# PIC18LF448 register map
Vendor: Microchip
Registers are 8-bit, read-write, no defined reset value unless marked. A register's access mark holds for its fields unless they carry their own. Addresses are absolute, and some are shared; only a register's first bit layout is shown; [hi:lo] are bit positions; {n}, {i} and the like mark numbered series; 'fields as' and 'values as' point back to an identical list.

## SFR
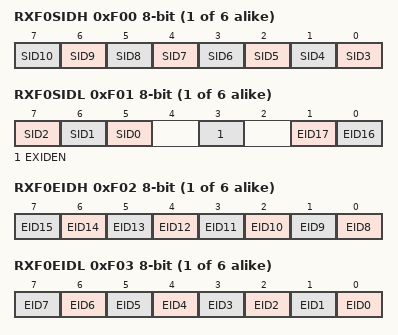
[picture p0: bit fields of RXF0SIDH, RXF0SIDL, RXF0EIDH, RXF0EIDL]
{0xF00+4i} RXF{i}SIDH (i=0..5) — (power-on value xxxxxxxx)
  [n-3] SID{n} (n=3..10)
{0xF01+4i} RXF{i}SIDL (i=0..5) — (power-on value xxx-x-xx)
  [7] SID2, [6] SID1, [5] SID0, [3] EXIDEN, [1] EID17, [0] EID16
{0xF02+4i} RXF{i}EIDH (i=0..5) — (power-on value xxxxxxxx)
  [n-8] EID{n} (n=8..15)
{0xF03+4i} RXF{i}EIDL (i=0..5) — (power-on value xxxxxxxx)
  [n] EID{n} (n=0..7)
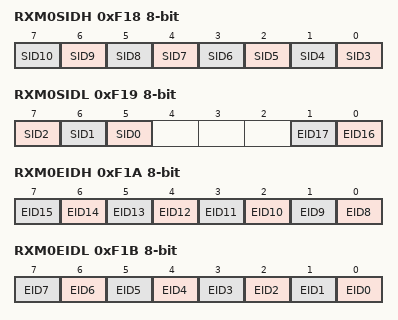
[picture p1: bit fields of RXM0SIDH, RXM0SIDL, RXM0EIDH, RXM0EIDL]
0xF18 RXM0SIDH — (power-on value xxxxxxxx)
  [n-3] SID{n} (n=3..10)
0xF19 RXM0SIDL — (power-on value xxx---xx)
  [7] SID2, [6] SID1, [5] SID0, [1] EID17, [0] EID16
0xF1A RXM0EIDH — (power-on value xxxxxxxx)
  [n-8] EID{n} (n=8..15)
0xF1B RXM0EIDL — (power-on value xxxxxxxx)
  [n] EID{n} (n=0..7)
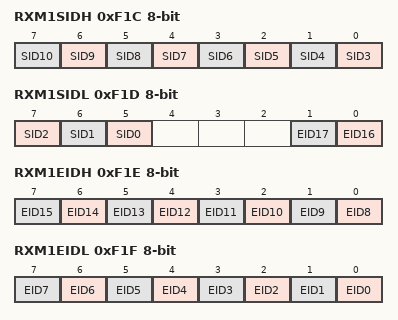
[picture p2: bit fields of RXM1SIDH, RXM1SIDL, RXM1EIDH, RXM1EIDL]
0xF1C RXM1SIDH — (power-on value xxxxxxxx)
  [n-3] SID{n} (n=3..10)
0xF1D RXM1SIDL — (power-on value xxx---xx)
  [7] SID2, [6] SID1, [5] SID0, [1] EID17, [0] EID16
0xF1E RXM1EIDH — (power-on value xxxxxxxx)
  [n-8] EID{n} (n=8..15)
0xF1F RXM1EIDL — (power-on value xxxxxxxx)
  [n] EID{n} (n=0..7)
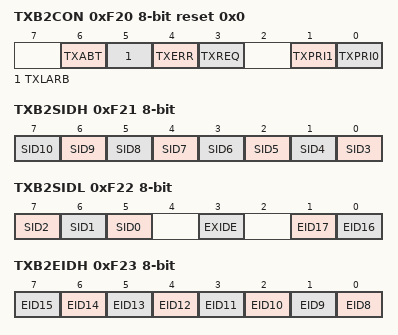
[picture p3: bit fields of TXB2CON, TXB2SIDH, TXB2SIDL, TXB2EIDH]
0xF20 TXB2CON reset 0x0
  [6] TXABT ro, [5] TXLARB ro, [4] TXERR ro, [3] TXREQ, [1] TXPRI1, [0] TXPRI0
0xF21 TXB2SIDH — (power-on value xxxxxxxx)
  [n-3] SID{n} (n=3..10)
0xF22 TXB2SIDL — (power-on value xxxxxxxx)
  [7] SID2, [6] SID1, [5] SID0, [3] EXIDE, [1] EID17, [0] EID16
0xF23 TXB2EIDH — (power-on value xxxxxxxx)
  [n-8] EID{n} (n=8..15)
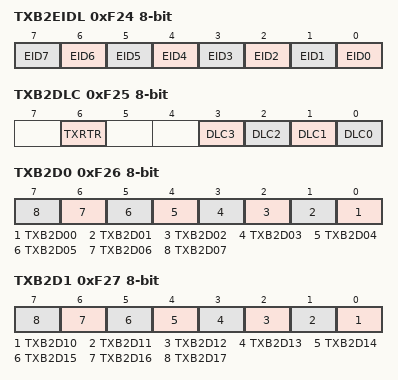
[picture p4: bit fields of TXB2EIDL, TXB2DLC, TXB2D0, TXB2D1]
0xF24 TXB2EIDL — (power-on value xxxxxxxx)
  [n] EID{n} (n=0..7)
0xF25 TXB2DLC — (power-on value -x--xxxx)
  [6] TXRTR, [n] DLC{n} (n=0..3)
0xF26 TXB2D0 — (power-on value xxxxxxxx)
  [n] TXB2D{n:02} (n=0..7)
0xF27 TXB2D1 — (power-on value xxxxxxxx)
  [n-10] TXB2D{n} (n=10..17)
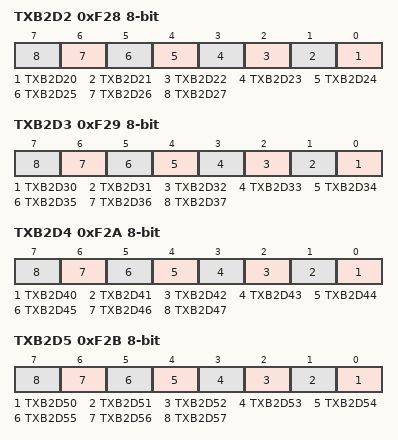
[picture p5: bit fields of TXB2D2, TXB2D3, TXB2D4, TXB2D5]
0xF28 TXB2D2 — (power-on value xxxxxxxx)
  [n-20] TXB2D{n} (n=20..27)
0xF29 TXB2D3 — (power-on value xxxxxxxx)
  [n-30] TXB2D{n} (n=30..37)
0xF2A TXB2D4 — (power-on value xxxxxxxx)
  [n-40] TXB2D{n} (n=40..47)
0xF2B TXB2D5 — (power-on value xxxxxxxx)
  [n-50] TXB2D{n} (n=50..57)
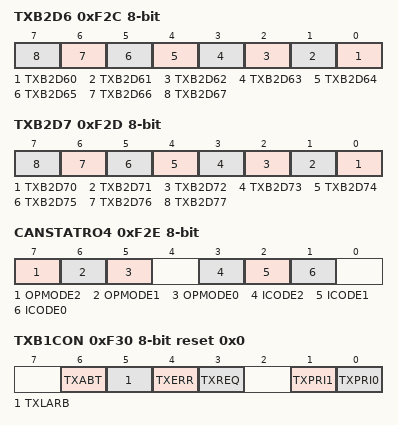
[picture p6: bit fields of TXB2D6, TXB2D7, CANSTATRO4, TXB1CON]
0xF2C TXB2D6 — (power-on value xxxxxxxx)
  [n-60] TXB2D{n} (n=60..67)
0xF2D TXB2D7 — (power-on value xxxxxxxx)
  [n-70] TXB2D{n} (n=70..77)
0xF2E CANSTATRO4 ro — (power-on value xxx-xxx-)
  [7] OPMODE2, [6] OPMODE1, [5] OPMODE0, [3] ICODE2, [2] ICODE1, [1] ICODE0
0xF30 TXB1CON reset 0x0
  fields as TXB2CON
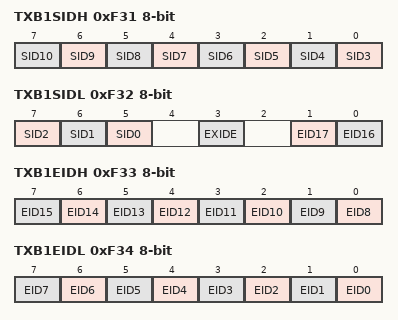
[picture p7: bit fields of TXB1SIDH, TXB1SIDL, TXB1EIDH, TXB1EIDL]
0xF31 TXB1SIDH — (power-on value xxxxxxxx)
  [n-3] SID{n} (n=3..10)
0xF32 TXB1SIDL — (power-on value xxx-x-xx)
  [7] SID2, [6] SID1, [5] SID0, [3] EXIDE, [1] EID17, [0] EID16
0xF33 TXB1EIDH — (power-on value xxxxxxxx)
  [n-8] EID{n} (n=8..15)
0xF34 TXB1EIDL — (power-on value xxxxxxxx)
  [n] EID{n} (n=0..7)
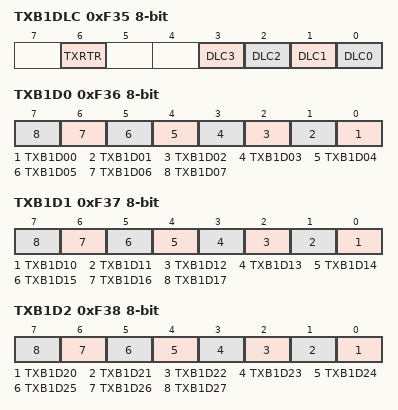
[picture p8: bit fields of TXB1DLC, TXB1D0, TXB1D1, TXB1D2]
0xF35 TXB1DLC — (power-on value -x--xxxx)
  [6] TXRTR, [n] DLC{n} (n=0..3)
0xF36 TXB1D0 — (power-on value xxxxxxxx)
  [n] TXB1D{n:02} (n=0..7)
0xF37 TXB1D1 — (power-on value xxxxxxxx)
  [n-10] TXB1D{n} (n=10..17)
0xF38 TXB1D2 — (power-on value xxxxxxxx)
  [n-20] TXB1D{n} (n=20..27)
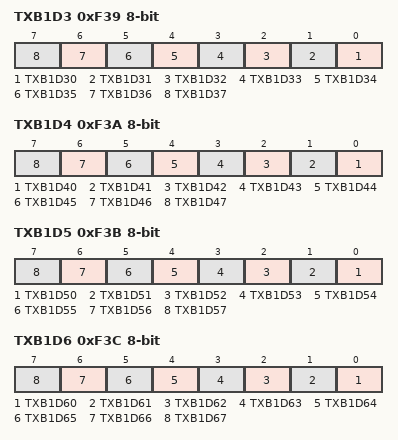
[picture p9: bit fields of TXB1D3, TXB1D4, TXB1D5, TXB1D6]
0xF39 TXB1D3 — (power-on value xxxxxxxx)
  [n-30] TXB1D{n} (n=30..37)
0xF3A TXB1D4 — (power-on value xxxxxxxx)
  [n-40] TXB1D{n} (n=40..47)
0xF3B TXB1D5 — (power-on value xxxxxxxx)
  [n-50] TXB1D{n} (n=50..57)
0xF3C TXB1D6 — (power-on value xxxxxxxx)
  [n-60] TXB1D{n} (n=60..67)
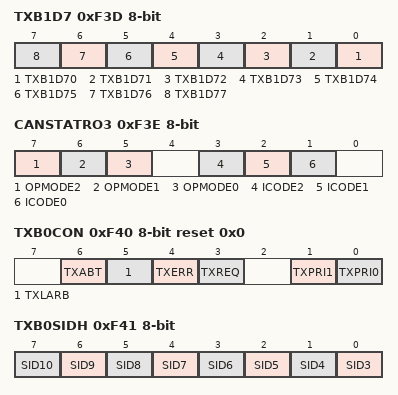
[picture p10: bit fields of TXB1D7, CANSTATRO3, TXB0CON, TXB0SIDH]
0xF3D TXB1D7 — (power-on value xxxxxxxx)
  [n-70] TXB1D{n} (n=70..77)
0xF3E CANSTATRO3 ro — (power-on value xxx-xxx-)
  fields as CANSTATRO4
0xF40 TXB0CON reset 0x0
  fields as TXB2CON
0xF41 TXB0SIDH — (power-on value xxxxxxxx)
  [n-3] SID{n} (n=3..10)
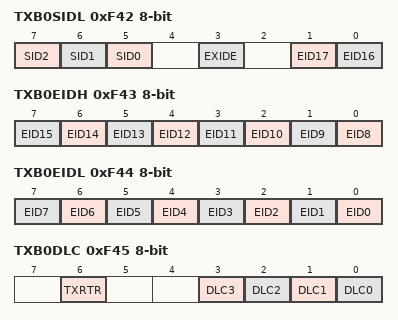
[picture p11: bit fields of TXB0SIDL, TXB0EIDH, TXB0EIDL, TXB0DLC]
0xF42 TXB0SIDL — (power-on value xxx-x-xx)
  [7] SID2, [6] SID1, [5] SID0, [3] EXIDE, [1] EID17, [0] EID16
0xF43 TXB0EIDH — (power-on value xxxxxxxx)
  [n-8] EID{n} (n=8..15)
0xF44 TXB0EIDL — (power-on value xxxxxxxx)
  [n] EID{n} (n=0..7)
0xF45 TXB0DLC — (power-on value -x--xxxx)
  [6] TXRTR, [n] DLC{n} (n=0..3)
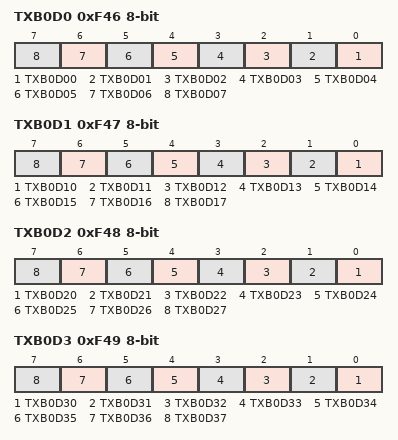
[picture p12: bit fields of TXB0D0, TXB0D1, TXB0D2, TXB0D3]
0xF46 TXB0D0 — (power-on value xxxxxxxx)
  [n] TXB0D{n:02} (n=0..7)
0xF47 TXB0D1 — (power-on value xxxxxxxx)
  [n-10] TXB0D{n} (n=10..17)
0xF48 TXB0D2 — (power-on value xxxxxxxx)
  [n-20] TXB0D{n} (n=20..27)
0xF49 TXB0D3 — (power-on value xxxxxxxx)
  [n-30] TXB0D{n} (n=30..37)
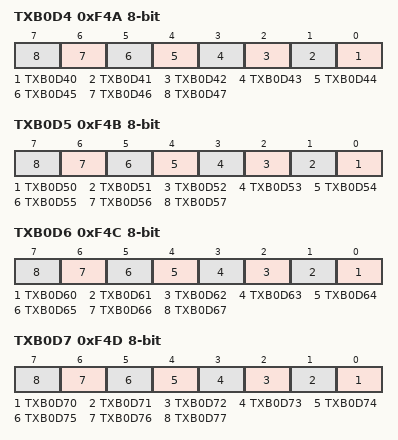
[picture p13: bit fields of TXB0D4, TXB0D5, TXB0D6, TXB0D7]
0xF4A TXB0D4 — (power-on value xxxxxxxx)
  [n-40] TXB0D{n} (n=40..47)
0xF4B TXB0D5 — (power-on value xxxxxxxx)
  [n-50] TXB0D{n} (n=50..57)
0xF4C TXB0D6 — (power-on value xxxxxxxx)
  [n-60] TXB0D{n} (n=60..67)
0xF4D TXB0D7 — (power-on value xxxxxxxx)
  [n-70] TXB0D{n} (n=70..77)
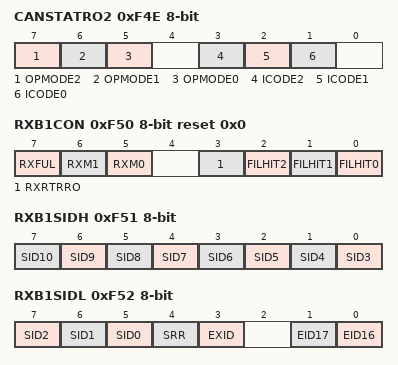
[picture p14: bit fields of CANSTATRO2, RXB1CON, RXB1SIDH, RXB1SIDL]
0xF4E CANSTATRO2 ro — (power-on value xxx-xxx-)
  fields as CANSTATRO4
0xF50 RXB1CON reset 0x0
  [7] RXFUL — (can only be cleared)
  [6] RXM1
  [5] RXM0
  [3] RXRTRRO ro
  [2] FILHIT2 ro
  [1] FILHIT1 ro
  [0] FILHIT0 ro
0xF51 RXB1SIDH — (power-on value xxxxxxxx)
  [n-3] SID{n} (n=3..10)
0xF52 RXB1SIDL — (power-on value xxxxxxxx)
  [7] SID2, [6] SID1, [5] SID0, [4] SRR, [3] EXID, [1] EID17, [0] EID16
0xF53 RXB1EIDH — (power-on value xxxxxxxx)
  [n-8] EID{n} (n=8..15)
0xF54 RXB1EIDL — (power-on value xxxxxxxx)
  [n] EID{n} (n=0..7)
0xF55 RXB1DLC — (power-on value -xxxxxxx)
  [6] RXRTR, [5] RB1, [4] RB0, [n] DLC{n} (n=0..3)
0xF56 RXB1D0 — (power-on value xxxxxxxx)
  [n] RXB1D{n:02} (n=0..7)
0xF57 RXB1D1 — (power-on value xxxxxxxx)
  [n-10] RXB1D{n} (n=10..17)
0xF58 RXB1D2 — (power-on value xxxxxxxx)
  [n-20] RXB1D{n} (n=20..27)
0xF59 RXB1D3 — (power-on value xxxxxxxx)
  [n-30] RXB1D{n} (n=30..37)
0xF5A RXB1D4 — (power-on value xxxxxxxx)
  [n-40] RXB1D{n} (n=40..47)
0xF5B RXB1D5 — (power-on value xxxxxxxx)
  [n-50] RXB1D{n} (n=50..57)
0xF5C RXB1D6 — (power-on value xxxxxxxx)
  [n-60] RXB1D{n} (n=60..67)
0xF5D RXB1D7 — (power-on value xxxxxxxx)
  [n-70] RXB1D{n} (n=70..77)
0xF5E CANSTATRO1 ro — (power-on value xxx-xxx-)
  fields as CANSTATRO4
0xF60 RXB0CON reset 0x0
  [7] RXFUL — (can only be cleared)
  [6] RXM1
  [5] RXM0
  [3] RXRTRRO ro
  [2] RXB0DBEN
  [1] JTOFF ro
  [0] FILHIT0
0xF61 RXB0SIDH — (power-on value xxxxxxxx)
  [n-3] SID{n} (n=3..10)
0xF62 RXB0SIDL — (power-on value xxxxxxxx)
  fields as RXB1SIDL
0xF63 RXB0EIDH — (power-on value xxxxxxxx)
  [n-8] EID{n} (n=8..15)
0xF64 RXB0EIDL — (power-on value xxxxxxxx)
  [n] EID{n} (n=0..7)
0xF65 RXB0DLC — (power-on value -xxxxxxx)
  [6] RXRTR, [5] RB1, [4] RB0, [n] DLC{n} (n=0..3)
0xF66 RXB0D0 — (power-on value xxxxxxxx)
  [n] RXB0D{n:02} (n=0..7)
0xF67 RXB0D1 — (power-on value xxxxxxxx)
  [n-10] RXB0D{n} (n=10..17)
0xF68 RXB0D2 — (power-on value xxxxxxxx)
  [n-20] RXB0D{n} (n=20..27)
0xF69 RXB0D3 — (power-on value xxxxxxxx)
  [n-30] RXB0D{n} (n=30..37)
0xF6A RXB0D4 — (power-on value xxxxxxxx)
  [n-40] RXB0D{n} (n=40..47)
0xF6B RXB0D5 — (power-on value xxxxxxxx)
  [n-50] RXB0D{n} (n=50..57)
0xF6C RXB0D6 — (power-on value xxxxxxxx)
  [n-60] RXB0D{n} (n=60..67)
0xF6D RXB0D7 — (power-on value xxxxxxxx)
  [n-70] RXB0D{n} (n=70..77)
0xF6E CANSTAT ro reset 0x80
  fields as CANSTATRO4
0xF6F CANCON reset 0x80
  [7] REQOP2, [6] REQOP1, [5] REQOP0, [4] ABAT, [3] WIN2, [2] WIN1, [1] WIN0
0xF70 BRGCON1 reset 0x0
  [7] SJW1, [6] SJW0, [n] BRP{n} (n=0..5)
0xF71 BRGCON2 reset 0x0
  [7] SEG2PHTS, [6] SAM, [5] SEG1PH2, [4] SEG1PH1, [3] SEG1PH0, [2] PRSEG2, [1] PRSEG1, [0] PRSEG0
0xF72 BRGCON3 reset 0x0
  [6] WAKFIL, [2] SEG2PH2, [1] SEG2PH1, [0] SEG2PH0
0xF73 CIOCON reset 0x0
  [5] ENDRHI, [4] CANCAP
0xF74 COMSTAT reset 0x0
  [7] RXB0OVFL — (can only be cleared)
  [6] RXB1OVFL — (can only be cleared)
  [5] TXBO ro
  [4] TXBP ro
  [3] RXBP ro
  [2] TXWARN ro
  [1] RXWARN ro
  [0] EWARN ro
0xF75 RXERRCNT ro reset 0x0
  [n] REC{n} (n=0..7)
0xF76 TXERRCNT ro reset 0x0
  [n] TEC{n} (n=0..7)
0xF80 PORTA — (power-on value -x0x0000)
  [n] RA{n} (n=0..6)
0xF81 PORTB — (power-on value xxxxxxxx)
  [n] RB{n} (n=0..7)
0xF82 PORTC — (power-on value xxxxxxxx)
  [n] RC{n} (n=0..7)
0xF83 PORTD — (power-on value xxxxxxxx)
  [n] RD{n} (n=0..7)
0xF84 PORTE — (power-on value -----xxx)
  [2] RE2, [1] RE1, [0] RE0
0xF89 LATA — (power-on value -xxxxxxx)
  [n] LATA{n} (n=0..6)
0xF8A LATB — (power-on value xxxxxxxx)
  [n] LATB{n} (n=0..7)
0xF8B LATC — (power-on value xxxxxxxx)
  [n] LATC{n} (n=0..7)
0xF8C LATD — (power-on value xxxxxxxx)
  [n] LATD{n} (n=0..7)
0xF8D LATE — (power-on value -----xxx)
  [2] LATE2, [1] LATE1, [0] LATE0
0xF92 TRISA reset 0x7F
  [n] TRISA{n} (n=0..6)
0xF93 TRISB reset 0xFF
  [n] TRISB{n} (n=0..7)
0xF94 TRISC reset 0xFF
  [n] TRISC{n} (n=0..7)
0xF95 TRISD reset 0xFF
  [n] TRISD{n} (n=0..7)
0xF96 TRISE reset 0x7
  [7] IBF, [6] OBF, [5] IBOV, [4] PSPMODE, [2] TRISE2, [1] TRISE1, [0] TRISE0
0xF9D PIE1 reset 0x0
  [7] PSPIE, [6] ADIE, [5] RCIE, [4] TXIE, [3] SSPIE, [2] CCP1IE, [1] TMR2IE, [0] TMR1IE
0xF9E PIR1 reset 0x0
  [7] PSPIF, [6] ADIF, [5] RCIF ro, [4] TXIF ro, [3] SSPIF, [2] CCP1IF, [1] TMR2IF, [0] TMR1IF
0xF9F IPR1 reset 0xFF
  [7] PSPIP, [6] ADIP, [5] RCIP, [4] TXIP, [3] SSPIP, [2] CCP1IP, [1] TMR2IP, [0] TMR1IP
0xFA0 PIE2 reset 0x0
  [6] CMIE, [4] EEIE, [3] BCLIE, [2] LVDIE, [1] TMR3IE, [0] ECCP1IE
0xFA1 PIR2 reset 0x0
  [6] CMIF, [4] EEIF, [3] BCLIF, [2] LVDIF, [1] TMR3IF, [0] ECCP1IF
0xFA2 IPR2 reset 0x5F
  [6] CMIP, [4] EEIP, [3] BCLIP, [2] LVDIP, [1] TMR3IP, [0] ECCP1IP
0xFA3 PIE3 reset 0x0
  [7] IRXIE, [6] WAKIE, [5] ERRIE, [4] TXB2IE, [3] TXB1IE, [2] TXB0IE, [1] RXB1IE, [0] RXB0IE
0xFA4 PIR3 reset 0x0
  [7] IRXIF, [6] WAKIF, [5] ERRIF, [4] TXB2IF, [3] TXB1IF, [2] TXB0IF, [1] RXB1IF, [0] RXB0IF
0xFA5 IPR3 reset 0xFF
  [7] IRXIP, [6] WAKIP, [5] ERRIP, [4] TXB2IP, [3] TXB1IP, [2] TXB0IP, [1] RXB1IP, [0] RXB0IP
0xFA6 EECON1 — (power-on value xx-0x000)
  [7] EEPGD
  [6] CFGS
  [4] FREE
  [3] WRERR
  [2] WREN
  [1] WR — (can only be set)
  [0] RD — (can only be set)
0xFA7 EECON2 wo
0xFA8 EEDATA reset 0x0
0xFA9 EEADR reset 0x0
0xFAB RCSTA — (power-on value 0000000x)
  [7] SPEN, [6] RX9, [5] SREN, [4] CREN, [3] ADDEN, [2] FERR ro, [1] OERR ro, [0] RX9D ro
0xFAC TXSTA reset 0x2
  [7] CSRC, [6] TX9, [5] TXEN, [4] SYNC, [2] BRGH, [1] TRMT ro, [0] TX9D
0xFAD TXREG wo reset 0x0
0xFAE RCREG ro reset 0x0
0xFAF SPBRG reset 0x0
0xFB1 T3CON reset 0x0
  [7] RD16, [6] T3ECCP1, [5:4] T3CKPS, [3] T3CCP1, [2] nT3SYNC, [1] TMR3CS, [0] TMR3ON
0xFB2 TMR3L — (power-on value xxxxxxxx)
0xFB3 TMR3H — (power-on value xxxxxxxx)
0xFB4 CMCON reset 0x0
  [7] C2OUT ro, [6] C1OUT ro, [5] C2INV, [4] C1INV, [3] CIS, [2:0] CM
0xFB5 CVRCON reset 0x0
  [7] CVREN, [6] CVROE, [5] CVRR, [4] CVRSS, [3:0] CVR
0xFB6 ECCPAS reset 0x0
  [7] ECCPASE, [6:4] ECCPAS, [3:2] PSSAC, [1:0] PSSBD
0xFB7 ECCP1DEL reset 0x0
  [7:0] EPDC
0xFBA ECCP1CON reset 0x0
  [7:6] EPWM1M, [5:4] EDC1B, [3:0] ECCP1M
0xFBB ECCPR1L — (power-on value xxxxxxxx)
0xFBC ECCPR1H — (power-on value xxxxxxxx)
0xFBD CCP1CON reset 0x0
  [5:4] DC1B, [3:0] CCP1M
0xFBE CCPR1L — (power-on value xxxxxxxx)
0xFBF CCPR1H — (power-on value xxxxxxxx)
0xFC1 ADCON1 reset 0x0
  [7] ADFM, [6] ADCS2, [3:0] PCFG
0xFC2 ADCON0 reset 0x0
  [7:6] ADCS, [5:3] CHS, [2] GO_nDONE, [0] ADON
0xFC3 ADRESL — (power-on value xxxxxxxx)
0xFC4 ADRESH — (power-on value xxxxxxxx)
0xFC5 SSPCON2 reset 0x0
  [7] GCEN, [6] ACKSTAT, [5] ACKDT, [4] ACKEN, [3] RCEN, [2] PEN, [1] RSEN, [0] SEN
0xFC6 SSPCON1 reset 0x0
  [7] WCOL, [6] SSPOV, [5] SSPEN, [4] CKP, [3:0] SSPM
0xFC7 SSPSTAT reset 0x0
  [7] SMP, [6] CKE, [5] D_nA, [4] P, [3] S, [2] R_nW, [1] UA, [0] BF
0xFC8 SSPADD reset 0x0
0xFC9 SSPBUF — (power-on value xxxxxxxx)
0xFCA T2CON reset 0x0
  [6:3] TOUTPS, [2] TMR2ON, [1:0] T2CKPS
0xFCB PR2 reset 0xFF
0xFCC TMR2 reset 0x0
0xFCD T1CON reset 0x0
  [7] RD16, [5:4] T1CKPS, [3] T1OSCEN, [2] nT1SYNC, [1] TMR1CS, [0] TMR1ON
0xFCE TMR1L — (power-on value xxxxxxxx)
0xFCF TMR1H — (power-on value xxxxxxxx)
0xFD0 RCON reset 0x1C
  [7] IPEN, [4] nRI, [3] nTO, [2] nPD, [1] nPOR, [0] nBOR
0xFD1 WDTCON reset 0x0
  [0] SWDTEN
0xFD2 LVDCON reset 0x5
  [5] IRVST, [4] LVDEN, [3:0] LVDL
0xFD3 OSCCON reset 0x0
  [0] SCS
0xFD5 T0CON reset 0xFF
  [7] TMR0ON, [6] T08BIT, [5] T0CS, [4] T0SE, [3] PSA, [2:0] T0PS
0xFD6 TMR0L — (power-on value xxxxxxxx)
0xFD7 TMR0H reset 0x0
0xFD8 STATUS — (power-on value ---xxxxx)
  [4] N, [3] OV, [2] Z, [1] DC, [0] C
0xFD9 FSR2L — (power-on value xxxxxxxx)
0xFDA FSR2H reset 0x0
  [3:0] FSR2H
0xFDB PLUSW2 access not given
0xFDC PREINC2 access not given
0xFDD POSTDEC2 access not given
0xFDE POSTINC2 access not given
0xFDF INDF2 access not given
0xFE0 BSR reset 0x0
  [3:0] BSR
0xFE1 FSR1L — (power-on value xxxxxxxx)
0xFE2 FSR1H reset 0x0
  [3:0] FSR1H
0xFE3 PLUSW1 access not given
0xFE4 PREINC1 access not given
0xFE5 POSTDEC1 access not given
0xFE6 POSTINC1 access not given
0xFE7 INDF1 access not given
0xFE8 WREG — (power-on value xxxxxxxx)
0xFE9 FSR0L — (power-on value xxxxxxxx)
0xFEA FSR0H reset 0x0
  [3:0] FSR0H
0xFEB PLUSW0 access not given
0xFEC PREINC0 access not given
0xFED POSTDEC0 access not given
0xFEE POSTINC0 access not given
0xFEF INDF0 access not given
0xFF0 INTCON3 reset 0xC0
  [7] INT2IP, [6] INT1IP, [4] INT2IE, [3] INT1IE, [1] INT2IF, [0] INT1IF
0xFF1 INTCON2 reset 0xE5
  [7] nRBPU, [6] INTEDG0, [5] INTEDG1, [4] INTEDG2, [2] TMR0IP, [0] RBIP
0xFF2 INTCON — (power-on value 0000000x)
  [7] GIE_GIEH, [6] PEIE_GIEL, [5] TMR0IE, [4] INT0IE, [3] RBIE, [2] TMR0IF, [1] INT0IF, [0] RBIF
0xFF3 PRODL — (power-on value xxxxxxxx)
0xFF4 PRODH — (power-on value xxxxxxxx)
0xFF5 TABLAT reset 0x0
0xFF6 TBLPTRL reset 0x0
0xFF7 TBLPTRH reset 0x0
0xFF8 TBLPTRU reset 0x0
  [5] ACSS, [4:0] TBLPTRU
0xFF9 PCL reset 0x0
0xFFA PCLATH reset 0x0
  [7:0] PCH
0xFFB PCLATU reset 0x0
  [4:0] PCU
0xFFC STKPTR reset 0x0
  [7] STKFUL — (can only be cleared)
  [6] STKUNF — (can only be cleared)
  [4:0] STKPTR
0xFFD TOSL reset 0x0
0xFFE TOSH reset 0x0
0xFFF TOSU reset 0x0
  [4:0] TOSU
